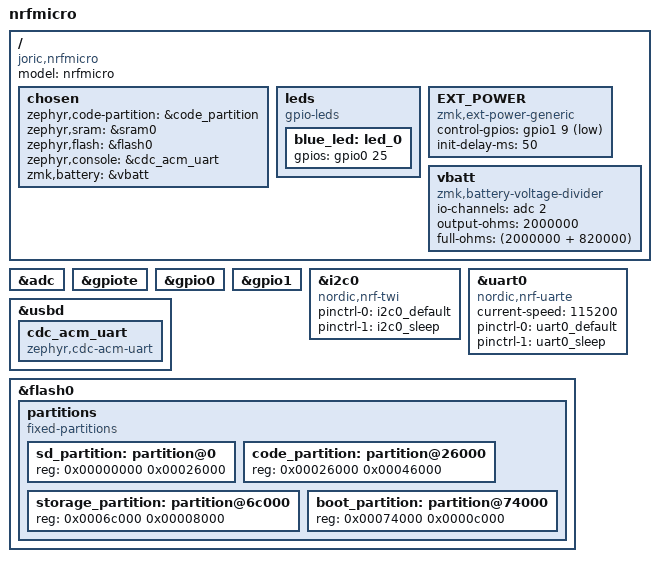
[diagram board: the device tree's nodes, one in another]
/*
 * Copyright (c) 2020 The ZMK Contributors
 *
 * SPDX-License-Identifier: MIT
 */

/dts-v1/;
#include <nordic/nrf52833_qiaa.dtsi>
#include "arduino_pro_micro_pins_52833.dtsi"
#include "nrfmicro-pinctrl.dtsi"

/ {
    model = "nrfmicro";
    compatible = "joric,nrfmicro";

    chosen {
        zephyr,code-partition = &code_partition;
        zephyr,sram = &sram0;
        zephyr,flash = &flash0;
        zephyr,console = &cdc_acm_uart;
        zmk,battery = &vbatt;
    };

    leds {
        compatible = "gpio-leds";
        blue_led: led_0 {
            gpios = <&gpio0 25 GPIO_ACTIVE_HIGH>;
        };
    };

    // Node name must match original "EXT_POWER" label to preserve user settings.
    EXT_POWER {
        compatible = "zmk,ext-power-generic";
        control-gpios = <&gpio1 9 GPIO_ACTIVE_LOW>;
        init-delay-ms = <50>;
    };

    vbatt: vbatt {
        compatible = "zmk,battery-voltage-divider";
        io-channels = <&adc 2>;
        output-ohms = <2000000>;
        full-ohms = <(2000000 + 820000)>;
    };
};

&adc {
    status = "okay";
};

&gpiote {
    status = "okay";
};

&gpio0 {
    status = "okay";
};

&gpio1 {
    status = "okay";
};

&i2c0 {
    compatible = "nordic,nrf-twi";
    pinctrl-0 = <&i2c0_default>;
    pinctrl-1 = <&i2c0_sleep>;
    pinctrl-names = "default", "sleep";
};

&uart0 {
    compatible = "nordic,nrf-uarte";
    current-speed = <115200>;
    pinctrl-0 = <&uart0_default>;
    pinctrl-1 = <&uart0_sleep>;
    pinctrl-names = "default", "sleep";
};

&usbd {
    status = "okay";
    cdc_acm_uart: cdc_acm_uart {
        compatible = "zephyr,cdc-acm-uart";
    };
};


&flash0 {
    /*
     * For more information, see:
     * http://docs.zephyrproject.org/latest/devices/dts/flash_partitions.html
     */
    partitions {
        compatible = "fixed-partitions";
        #address-cells = <1>;
        #size-cells = <1>;

        sd_partition: partition@0 {
            reg = <0x00000000 0x00026000>;
        };
        code_partition: partition@26000 {
            reg = <0x00026000 0x00046000>;
        };

        /*
         * The flash starting at 0x0006c000 and ending at
         * 0x00073fff is reserved for use by the application.
         */

        /*
         * Storage partition will be used by FCB/LittleFS/NVS
         * if enabled.
         */
        storage_partition: partition@6c000 {
            reg = <0x0006c000 0x00008000>;
        };

        boot_partition: partition@74000 {
            reg = <0x00074000 0x0000c000>;
        };
    };
};
